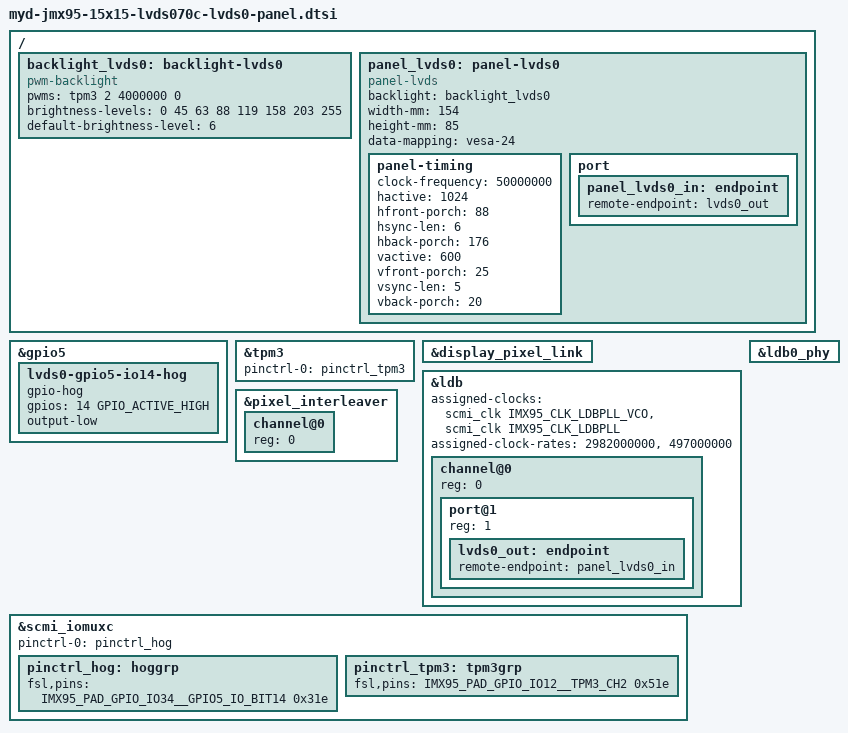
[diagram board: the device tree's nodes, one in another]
// SPDX-License-Identifier: GPL-2.0+
/*
 * Copyright 2026 MYIR
 */

/ {
	backlight_lvds0: backlight-lvds0 {
		compatible = "pwm-backlight";
		pwms = <&tpm3 2 4000000 0>;
		brightness-levels = <0 45 63 88 119 158 203 255>;
		default-brightness-level = <6>;
	};

	panel_lvds0: panel-lvds0 {
		compatible = "panel-lvds";
		backlight = <&backlight_lvds0>;
		width-mm = <154>;
		height-mm = <85>;
		data-mapping = "vesa-24";
		panel-timing {
			clock-frequency = <50000000>;
			hactive = <1024>;
			hfront-porch = <88>;
			hsync-len = <6>;
			hback-porch = <176>;
			vactive = <600>;
			vfront-porch = <25>;
			vsync-len = <5>;
			vback-porch = <20>;
		};

		port {
			panel_lvds0_in: endpoint {
				remote-endpoint = <&lvds0_out>;
			};
		};
	};
};

&gpio5 {
	lvds0-gpio5-io14-hog {
		gpio-hog;
		gpios = <14 GPIO_ACTIVE_HIGH>;
		output-low;
		status = "okay";
	};
};

&tpm3 {
	pinctrl-names = "default";
	pinctrl-0 = <&pinctrl_tpm3>;
	status = "okay";
};

&display_pixel_link {
	status = "okay";
};

&ldb {
	#address-cells = <1>;
	#size-cells = <0>;
	assigned-clocks = <&scmi_clk IMX95_CLK_LDBPLL_VCO>,
			  <&scmi_clk IMX95_CLK_LDBPLL>;
	assigned-clock-rates = <2982000000>, <497000000>;
	status = "okay";

	channel@0 {
		#address-cells = <1>;
		#size-cells = <0>;
		reg = <0>;
		status = "okay";

		port@1 {
			reg = <1>;

			lvds0_out: endpoint {
				remote-endpoint = <&panel_lvds0_in>;
			};
		};
	};
};

&ldb0_phy {
	status = "okay";
};

&pixel_interleaver {
	#address-cells = <1>;
	#size-cells = <0>;
	status = "okay";

	channel@0 {
		reg = <0>;
		status = "okay";
	};
};

&scmi_iomuxc {
	pinctrl-names = "default";
	pinctrl-0 = <&pinctrl_hog>;
	pinctrl_hog: hoggrp {
		fsl,pins = <
			IMX95_PAD_GPIO_IO34__GPIO5_IO_BIT14    0x31e
		>;
	};

	pinctrl_tpm3: tpm3grp {
		fsl,pins = <
			IMX95_PAD_GPIO_IO12__TPM3_CH2	0x51e
		>;
	};
};
